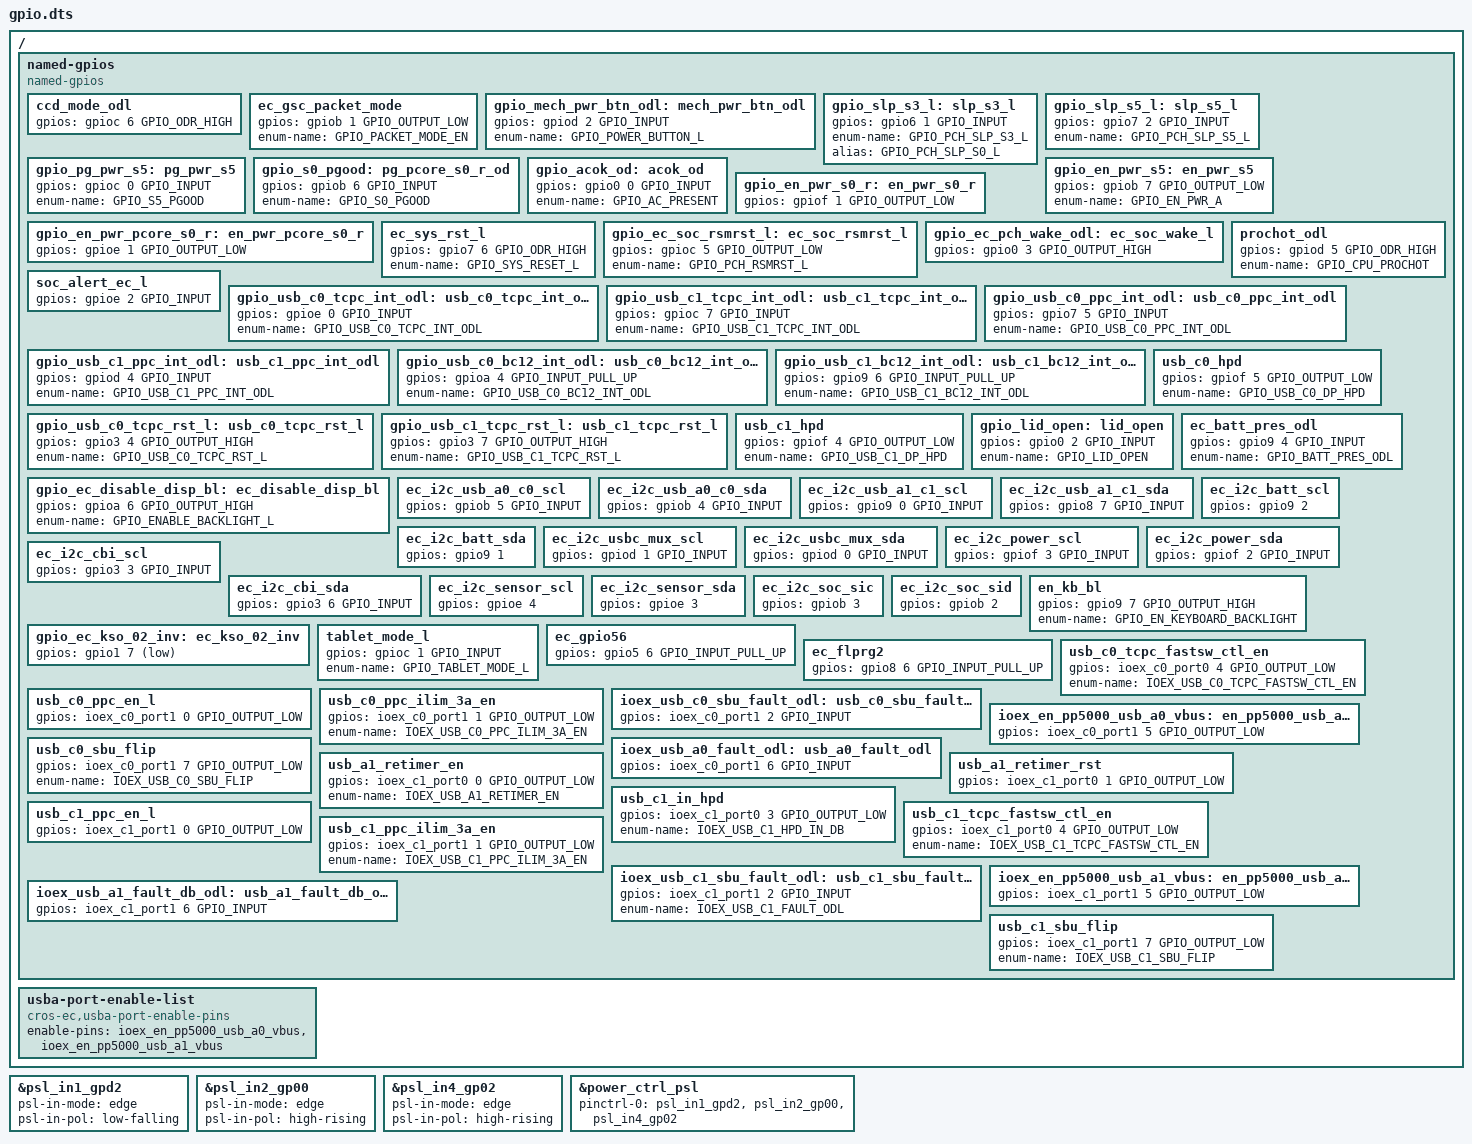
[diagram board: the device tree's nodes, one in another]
/* Copyright 2021 The Chromium OS Authors. All rights reserved.
 * Use of this source code is governed by a BSD-style license that can be
 * found in the LICENSE file.
 */

/ {
	/* GPIOs shared by all boards */
	named-gpios {
		compatible = "named-gpios";

		ccd_mode_odl {
			gpios = <&gpioc 6 GPIO_ODR_HIGH>;
		};
		ec_gsc_packet_mode {
			gpios = <&gpiob 1 GPIO_OUTPUT_LOW>;
			enum-name = "GPIO_PACKET_MODE_EN";
		};
		gpio_mech_pwr_btn_odl: mech_pwr_btn_odl {
			gpios = <&gpiod 2 GPIO_INPUT>;
			enum-name = "GPIO_POWER_BUTTON_L";
		};
		gpio_slp_s3_l: slp_s3_l {
			gpios = <&gpio6 1 GPIO_INPUT>;
			enum-name = "GPIO_PCH_SLP_S3_L";
			alias = "GPIO_PCH_SLP_S0_L";
		};
		gpio_slp_s5_l: slp_s5_l {
			gpios = <&gpio7 2 GPIO_INPUT>;
			enum-name = "GPIO_PCH_SLP_S5_L";
		};
		gpio_pg_pwr_s5: pg_pwr_s5 {
			gpios = <&gpioc 0 GPIO_INPUT>;
			enum-name = "GPIO_S5_PGOOD";
		};
		gpio_s0_pgood: pg_pcore_s0_r_od {
			gpios = <&gpiob 6 GPIO_INPUT>;
			enum-name = "GPIO_S0_PGOOD";
		};
		gpio_acok_od: acok_od {
			gpios = <&gpio0 0 GPIO_INPUT>;
			enum-name = "GPIO_AC_PRESENT";
		};
		gpio_en_pwr_s5: en_pwr_s5 {
			gpios = <&gpiob 7 GPIO_OUTPUT_LOW>;
			enum-name = "GPIO_EN_PWR_A";
		};
		gpio_en_pwr_s0_r: en_pwr_s0_r {
			gpios = <&gpiof 1 GPIO_OUTPUT_LOW>;
		};
		gpio_en_pwr_pcore_s0_r: en_pwr_pcore_s0_r {
			gpios = <&gpioe 1 GPIO_OUTPUT_LOW>;
		};
		ec_sys_rst_l {
			gpios = <&gpio7 6 GPIO_ODR_HIGH>;
			enum-name = "GPIO_SYS_RESET_L";
		};
		gpio_ec_soc_rsmrst_l: ec_soc_rsmrst_l {
			gpios = <&gpioc 5 GPIO_OUTPUT_LOW>;
			enum-name = "GPIO_PCH_RSMRST_L";
		};
		gpio_ec_pch_wake_odl: ec_soc_wake_l {
			gpios = <&gpio0 3 GPIO_OUTPUT_HIGH>;
		};
		prochot_odl {
			gpios = <&gpiod 5 GPIO_ODR_HIGH>;
			enum-name = "GPIO_CPU_PROCHOT";
		};
		soc_alert_ec_l {
			gpios = <&gpioe 2 GPIO_INPUT>;
		};
		gpio_usb_c0_tcpc_int_odl: usb_c0_tcpc_int_odl {
			gpios = <&gpioe 0 GPIO_INPUT>;
			enum-name = "GPIO_USB_C0_TCPC_INT_ODL";
		};
		gpio_usb_c1_tcpc_int_odl: usb_c1_tcpc_int_odl {
			gpios = <&gpioc 7 GPIO_INPUT>;
			enum-name = "GPIO_USB_C1_TCPC_INT_ODL";
		};
		gpio_usb_c0_ppc_int_odl: usb_c0_ppc_int_odl {
			gpios = <&gpio7 5 GPIO_INPUT>;
			enum-name = "GPIO_USB_C0_PPC_INT_ODL";
		};
		gpio_usb_c1_ppc_int_odl: usb_c1_ppc_int_odl {
			gpios = <&gpiod 4 GPIO_INPUT>;
			enum-name = "GPIO_USB_C1_PPC_INT_ODL";
		};
		gpio_usb_c0_bc12_int_odl: usb_c0_bc12_int_odl {
			gpios = <&gpioa 4 GPIO_INPUT_PULL_UP>;
			enum-name = "GPIO_USB_C0_BC12_INT_ODL";
		};
		gpio_usb_c1_bc12_int_odl: usb_c1_bc12_int_odl {
			gpios = <&gpio9 6 GPIO_INPUT_PULL_UP>;
			enum-name = "GPIO_USB_C1_BC12_INT_ODL";
		};
		gpio_usb_c0_tcpc_rst_l: usb_c0_tcpc_rst_l {
			gpios = <&gpio3 4 GPIO_OUTPUT_HIGH>;
			enum-name = "GPIO_USB_C0_TCPC_RST_L";
		};
		gpio_usb_c1_tcpc_rst_l: usb_c1_tcpc_rst_l {
			gpios = <&gpio3 7 GPIO_OUTPUT_HIGH>;
			enum-name = "GPIO_USB_C1_TCPC_RST_L";
		};
		usb_c0_hpd {
			gpios = <&gpiof 5 GPIO_OUTPUT_LOW>;
			enum-name = "GPIO_USB_C0_DP_HPD";
		};
		usb_c1_hpd {
			gpios = <&gpiof 4 GPIO_OUTPUT_LOW>;
			enum-name = "GPIO_USB_C1_DP_HPD";
		};
		gpio_lid_open: lid_open {
			gpios = <&gpio0 2 GPIO_INPUT>;
			enum-name = "GPIO_LID_OPEN";
		};
		ec_batt_pres_odl {
			gpios = <&gpio9 4 GPIO_INPUT>;
			enum-name = "GPIO_BATT_PRES_ODL";
		};
		gpio_ec_disable_disp_bl: ec_disable_disp_bl {
			gpios = <&gpioa 6 GPIO_OUTPUT_HIGH>;
			enum-name = "GPIO_ENABLE_BACKLIGHT_L";
		};
		ec_i2c_usb_a0_c0_scl {
			gpios = <&gpiob 5 GPIO_INPUT>;
		};
		ec_i2c_usb_a0_c0_sda {
			gpios = <&gpiob 4 GPIO_INPUT>;
		};
		ec_i2c_usb_a1_c1_scl {
			gpios = <&gpio9 0 GPIO_INPUT>;
		};
		ec_i2c_usb_a1_c1_sda {
			gpios = <&gpio8 7 GPIO_INPUT>;
		};
		ec_i2c_batt_scl {
			gpios = <&gpio9 2 (GPIO_INPUT | GPIO_VOLTAGE_1P8)>;
		};
		ec_i2c_batt_sda {
			gpios = <&gpio9 1 (GPIO_INPUT | GPIO_VOLTAGE_1P8)>;
		};
		ec_i2c_usbc_mux_scl {
			gpios = <&gpiod 1 GPIO_INPUT>;
		};
		ec_i2c_usbc_mux_sda {
			gpios = <&gpiod 0 GPIO_INPUT>;
		};
		ec_i2c_power_scl {
			gpios = <&gpiof 3 GPIO_INPUT>;
		};
		ec_i2c_power_sda {
			gpios = <&gpiof 2 GPIO_INPUT>;
		};
		ec_i2c_cbi_scl {
			gpios = <&gpio3 3 GPIO_INPUT>;
		};
		ec_i2c_cbi_sda {
			gpios = <&gpio3 6 GPIO_INPUT>;
		};
		ec_i2c_sensor_scl {
			gpios = <&gpioe 4 (GPIO_INPUT | GPIO_VOLTAGE_1P8)>;
		};
		ec_i2c_sensor_sda {
			gpios = <&gpioe 3 (GPIO_INPUT | GPIO_VOLTAGE_1P8)>;
		};
		ec_i2c_soc_sic {
			gpios = <&gpiob 3 (GPIO_INPUT | GPIO_VOLTAGE_1P8)>;
		};
		ec_i2c_soc_sid {
			gpios = <&gpiob 2 (GPIO_INPUT | GPIO_VOLTAGE_1P8)>;
		};
		en_kb_bl {
			gpios = <&gpio9 7 GPIO_OUTPUT_HIGH>;
			enum-name = "GPIO_EN_KEYBOARD_BACKLIGHT";
		};
		gpio_ec_kso_02_inv: ec_kso_02_inv {
			gpios = <&gpio1 7 (GPIO_OUTPUT_LOW | GPIO_ACTIVE_LOW)>;
		};
		tablet_mode_l {
			gpios = <&gpioc 1 GPIO_INPUT>;
			enum-name = "GPIO_TABLET_MODE_L";
		};
		ec_gpio56 {
			gpios = <&gpio5 6 GPIO_INPUT_PULL_UP>;
		};
		ec_flprg2 {
			gpios = <&gpio8 6 GPIO_INPUT_PULL_UP>;
		};

		usb_c0_tcpc_fastsw_ctl_en {
			gpios = <&ioex_c0_port0 4 GPIO_OUTPUT_LOW>;
			enum-name = "IOEX_USB_C0_TCPC_FASTSW_CTL_EN";
		};
		usb_c0_ppc_en_l {
			gpios = <&ioex_c0_port1 0 GPIO_OUTPUT_LOW>;
		};
		usb_c0_ppc_ilim_3a_en {
			gpios = <&ioex_c0_port1 1 GPIO_OUTPUT_LOW>;
			enum-name = "IOEX_USB_C0_PPC_ILIM_3A_EN";
		};
		ioex_usb_c0_sbu_fault_odl: usb_c0_sbu_fault_odl {
			gpios = <&ioex_c0_port1 2 GPIO_INPUT>;
		};
		ioex_en_pp5000_usb_a0_vbus: en_pp5000_usb_a0_vbus {
			gpios = <&ioex_c0_port1 5 GPIO_OUTPUT_LOW>;
		};
		ioex_usb_a0_fault_odl: usb_a0_fault_odl {
			gpios = <&ioex_c0_port1 6 GPIO_INPUT>;
		};
		usb_c0_sbu_flip {
			gpios = <&ioex_c0_port1 7 GPIO_OUTPUT_LOW>;
			enum-name = "IOEX_USB_C0_SBU_FLIP";
		};

		usb_a1_retimer_en {
			gpios = <&ioex_c1_port0 0 GPIO_OUTPUT_LOW>;
			enum-name = "IOEX_USB_A1_RETIMER_EN";
		};
		usb_a1_retimer_rst {
			gpios = <&ioex_c1_port0 1 GPIO_OUTPUT_LOW>;
		};
		usb_c1_in_hpd {
			gpios = <&ioex_c1_port0 3 GPIO_OUTPUT_LOW>;
			enum-name = "IOEX_USB_C1_HPD_IN_DB";
		};
		usb_c1_tcpc_fastsw_ctl_en {
			gpios = <&ioex_c1_port0 4 GPIO_OUTPUT_LOW>;
			enum-name = "IOEX_USB_C1_TCPC_FASTSW_CTL_EN";
		};
		usb_c1_ppc_en_l {
			gpios = <&ioex_c1_port1 0 GPIO_OUTPUT_LOW>;
		};
		usb_c1_ppc_ilim_3a_en {
			gpios = <&ioex_c1_port1 1 GPIO_OUTPUT_LOW>;
			enum-name = "IOEX_USB_C1_PPC_ILIM_3A_EN";
		};
		ioex_usb_c1_sbu_fault_odl: usb_c1_sbu_fault_odl {
			gpios = <&ioex_c1_port1 2 GPIO_INPUT>;
			enum-name = "IOEX_USB_C1_FAULT_ODL";
		};
		ioex_en_pp5000_usb_a1_vbus: en_pp5000_usb_a1_vbus {
			gpios = <&ioex_c1_port1 5 GPIO_OUTPUT_LOW>;
		};
		ioex_usb_a1_fault_db_odl: usb_a1_fault_db_odl {
			gpios = <&ioex_c1_port1 6 GPIO_INPUT>;
		};
		usb_c1_sbu_flip {
			gpios = <&ioex_c1_port1 7 GPIO_OUTPUT_LOW>;
			enum-name = "IOEX_USB_C1_SBU_FLIP";
		};
	};

	usba-port-enable-list {
		compatible = "cros-ec,usba-port-enable-pins";
		enable-pins = <&ioex_en_pp5000_usb_a0_vbus
			       &ioex_en_pp5000_usb_a1_vbus>;
	};
};

/* PSL input pads*/
&psl_in1_gpd2 {
	/* MECH_PWR_BTN_ODL */
	psl-in-mode = "edge";
	psl-in-pol = "low-falling";
};

&psl_in2_gp00 {
	/* ACOK_OD */
	psl-in-mode = "edge";
	psl-in-pol = "high-rising";
};

&psl_in4_gp02 {
	/* LID_OPEN */
	psl-in-mode = "edge";
	psl-in-pol = "high-rising";
};

/* Power domain device controlled by PSL (Power Switch Logic) IO pads */
&power_ctrl_psl {
	status = "okay";
	pinctrl-names = "sleep";
	pinctrl-0 = <&psl_in1_gpd2 &psl_in2_gp00 &psl_in4_gp02>;
};
